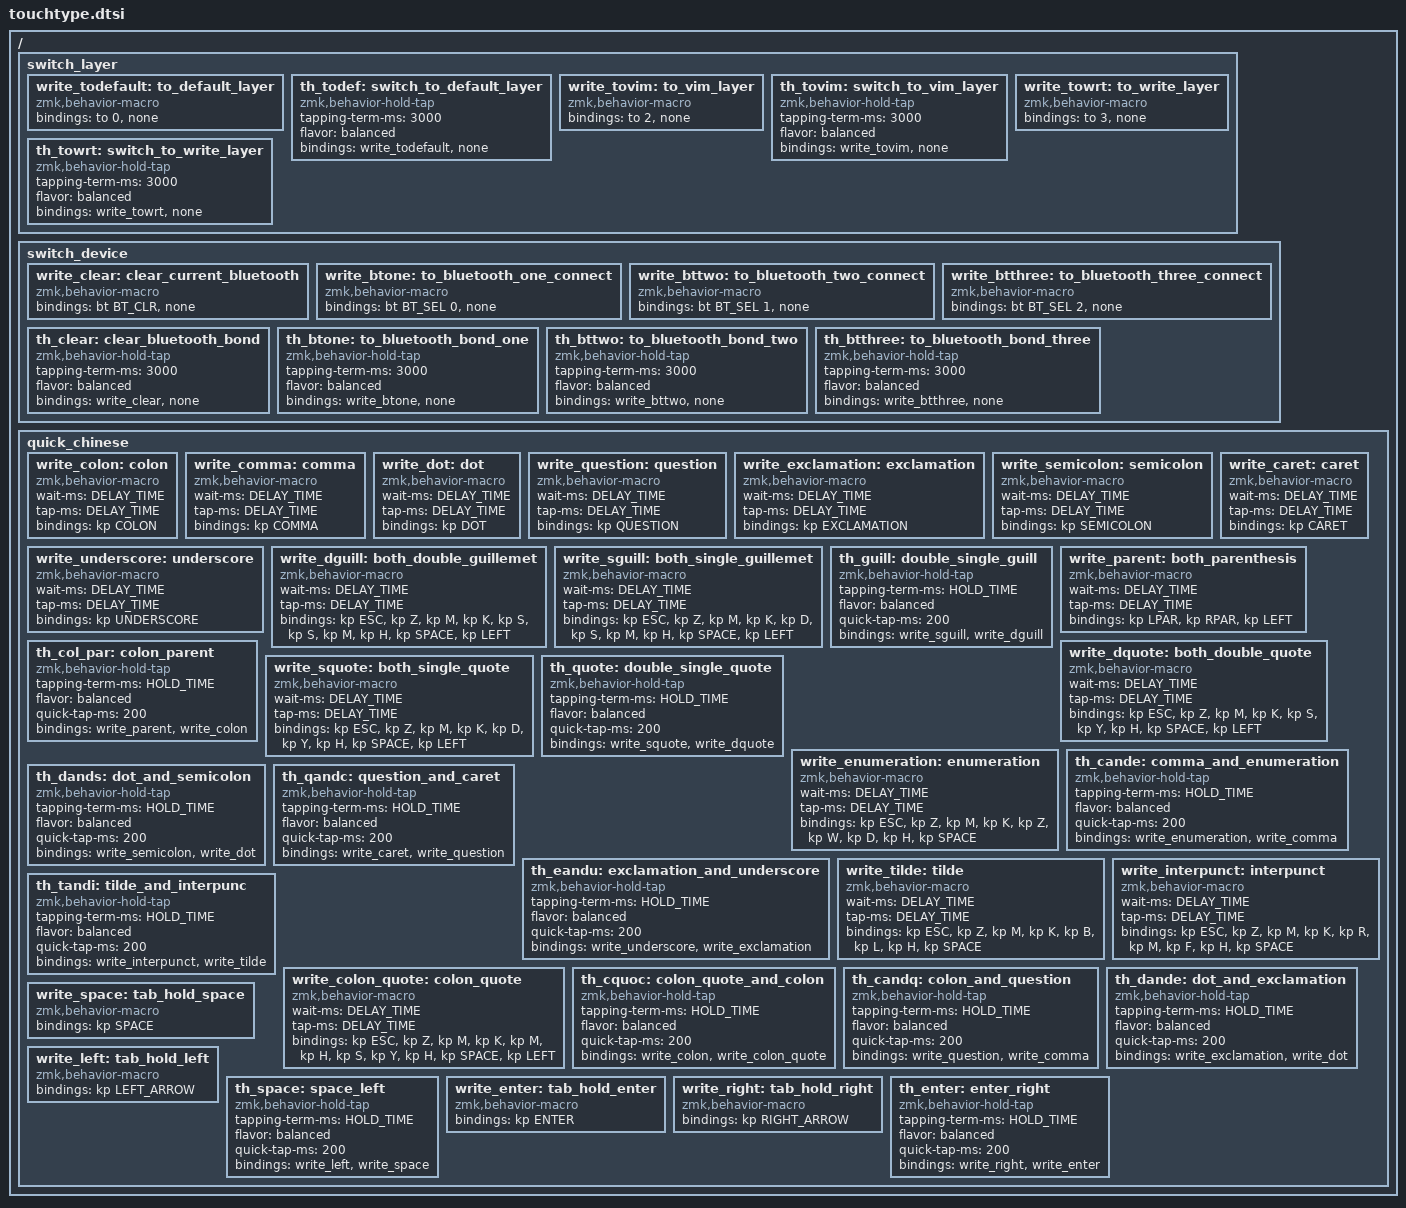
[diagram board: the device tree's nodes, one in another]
// 自定义符号快捷输入

#define DELAY_TIME <5> // 定义宏延迟时间为 10 毫秒
#define HOLD_TIME <500> // 定义短按、长按时间阀值


/ { 
    // 切换到不同编辑模式层
    switch_layer {
        // 如果有自定义行为，就需要把 &none 更换成真实的 behavior，例如 <&to 0 &kp A>，下面其实类似
        write_todefault: to_default_layer {
            compatible = "zmk,behavior-macro";
            #binding-cells = <0>;   
            bindings = <&to 0 &none>;
        }; 

         // 短按空按键 ，长按切换到默认 layer 0
        th_todef: switch_to_default_layer {
            compatible = "zmk,behavior-hold-tap";
            #binding-cells = <2>;
            tapping-term-ms = <3000>;      // 短按判定时间，可调
            flavor = "balanced";          // 推荐 balanced，更自然
            // 长按在前，短按在后；同时适用于 windows 和 linux 输入法
            bindings = <&write_todefault>,<&none>;
        }; 

        write_tovim: to_vim_layer {
            compatible = "zmk,behavior-macro";
            #binding-cells = <0>;   
            bindings = <&to 2 &none>;
        }; 

         // 短按空按键 ，长按切换到 vim 编辑层 layer 1
        th_tovim: switch_to_vim_layer {
            compatible = "zmk,behavior-hold-tap";
            #binding-cells = <2>;
            tapping-term-ms = <3000>;      // 短按判定时间，可调
            flavor = "balanced";          // 推荐 balanced，更自然
            // 长按在前，短按在后；同时适用于 windows 和 linux 输入法
            bindings = <&write_tovim>,<&none>;
        }; 

        write_towrt: to_write_layer {
            compatible = "zmk,behavior-macro";
            #binding-cells = <0>;   
            bindings = <&to 3 &none>;
        }; 

         // 短按空按键 ，长按切换到写作模式层 layer 2
        th_towrt: switch_to_write_layer {
            compatible = "zmk,behavior-hold-tap";
            #binding-cells = <2>;
            tapping-term-ms = <3000>;      // 短按判定时间，可调
            flavor = "balanced";          // 推荐 balanced，更自然
            // 长按在前，短按在后；同时适用于 windows 和 linux 输入法
            bindings = <&write_towrt>,<&none>;
        }; 

    };

    // 切换不同的连接主机
    switch_device {
        // 主机清除当前槽位的匹配信息之后，需要在 zmk 的相同槽位清除匹配信息，它不会影响其它槽位的匹配信息
        // 如果有自定义行为，就需要把 &none 更换成真实的 behavior，下面其实类似
        write_clear: clear_current_bluetooth {
            compatible = "zmk,behavior-macro";
            #binding-cells = <0>;   
            bindings = <&bt BT_CLR &none>;
        };

        // 切换到槽位 0 的蓝牙连接
        write_btone: to_bluetooth_one_connect {
            compatible = "zmk,behavior-macro";
            #binding-cells = <0>;   
            bindings = <&bt BT_SEL 0 &none>;
        };

        // 切换到槽位 1 的蓝牙连接
        write_bttwo: to_bluetooth_two_connect {
            compatible = "zmk,behavior-macro";
            #binding-cells = <0>;   
            bindings = <&bt BT_SEL 1 &none>;
        };

        //切换到槽位 2 的蓝牙连接 
        write_btthree: to_bluetooth_three_connect {
            compatible = "zmk,behavior-macro";
            #binding-cells = <0>;   
            bindings = <&bt BT_SEL 2 &none>;
        };   
         // 短按空按键 ，长按清除当前槽位的蓝牙连接匹配
        th_clear: clear_bluetooth_bond {
            compatible = "zmk,behavior-hold-tap";
            #binding-cells = <2>;
            tapping-term-ms = <3000>;      // 短按判定时间，可调
            flavor = "balanced";          // 推荐 balanced，更自然
            // 长按在前，短按在后；同时适用于 windows 和 linux 输入法
            bindings = <&write_clear>,<&none>;
        };   

         // 短按空按键 ，长按切换到蓝牙连接槽位 0
        th_btone: to_bluetooth_bond_one {
            compatible = "zmk,behavior-hold-tap";
            #binding-cells = <2>;
            tapping-term-ms = <3000>;      // 短按判定时间，可调
            flavor = "balanced";          // 推荐 balanced，更自然
            // 长按在前，短按在后；同时适用于 windows 和 linux 输入法
            bindings = <&write_btone>,<&none>;
        };  

         // 短按空按键 ，长按切换到蓝牙连接槽位 1
        th_bttwo: to_bluetooth_bond_two {
            compatible = "zmk,behavior-hold-tap";
            #binding-cells = <2>;
            tapping-term-ms = <3000>;      // 短按判定时间，可调
            flavor = "balanced";          // 推荐 balanced，更自然
            // 长按在前，短按在后；同时适用于 windows 和 linux 输入法
            bindings = <&write_bttwo>,<&none>;
        };       

         // 短按空按键 ，长按切换到蓝牙连接槽位 0
        th_btthree: to_bluetooth_bond_three {
            compatible = "zmk,behavior-hold-tap";
            #binding-cells = <2>;
            tapping-term-ms = <3000>;      // 短按判定时间，可调
            flavor = "balanced";          // 推荐 balanced，更自然
            // 长按在前，短按在后；同时适用于 windows 和 linux 输入法
            bindings = <&write_btthree>,<&none>;
        };    
    };

    // 快速输入中文符号
    quick_chinese {
        // ------------------- 一些共用按键 ------------------
        // 输入 ： 冒号
        write_colon: colon {
            compatible = "zmk,behavior-macro";
            #binding-cells = <0>;   
            wait-ms = DELAY_TIME;
            tap-ms = DELAY_TIME;
            // linux不需要额外设置，windows不确定需不需要额外设置
            bindings = <&kp COLON>;
        };

        // 输入 ， 逗号
        write_comma: comma {
            compatible = "zmk,behavior-macro";
            #binding-cells = <0>;   
            wait-ms = DELAY_TIME;
            tap-ms = DELAY_TIME;
            // linux不需要额外设置，windows不确定需不需要额外设置
            bindings = <&kp COMMA>;
        };

        // 输入 。 句号
        write_dot: dot {
            compatible = "zmk,behavior-macro";
            #binding-cells = <0>;   
            wait-ms = DELAY_TIME;
            tap-ms = DELAY_TIME;
            // linux不需要额外设置，windows不确定需不需要额外设置
            bindings = <&kp DOT>;
        };

        // 输入 ？ 问号
        write_question: question {
            compatible = "zmk,behavior-macro";
            #binding-cells = <0>;   
            wait-ms = DELAY_TIME;
            tap-ms = DELAY_TIME;
            // linux不需要额外设置，windows不确定需不需要额外设置
            bindings = <&kp QUESTION>;
        };

        // 输入 ！ 感叹号
        write_exclamation: exclamation {
            compatible = "zmk,behavior-macro";
            #binding-cells = <0>;   
            wait-ms = DELAY_TIME;
            tap-ms = DELAY_TIME;
            // linux不需要额外设置，windows不确定需不需要额外设置
            bindings = <&kp EXCLAMATION>;
        };   

        // 输入 ； 分号
        write_semicolon: semicolon {
            compatible = "zmk,behavior-macro";
            #binding-cells = <0>;   
            wait-ms = DELAY_TIME;
            tap-ms = DELAY_TIME;
            // linux不需要额外设置，windows不确定需不需要额外设置
            bindings = <&kp SEMICOLON>;
        };

        // 输入 …… 分号
        write_caret: caret {
            compatible = "zmk,behavior-macro";
            #binding-cells = <0>;   
            wait-ms = DELAY_TIME;
            tap-ms = DELAY_TIME;
            // linux不需要额外设置，windows不确定需不需要额外设置
            bindings = <&kp CARET>;
        };

        // 输入 —— 分号
        write_underscore: underscore {
            compatible = "zmk,behavior-macro";
            #binding-cells = <0>;   
            wait-ms = DELAY_TIME;
            tap-ms = DELAY_TIME;
            // linux不需要额外设置，windows不确定需不需要额外设置
            bindings = <&kp UNDERSCORE>;
        };

        // ----------------- R1C4 默认键位值 -----------------
        // 输入左、右双书名号、左方向键
        write_dguill: both_double_guillemet {
            compatible = "zmk,behavior-macro";
            #binding-cells = <0>;   
            wait-ms = DELAY_TIME;
            tap-ms = DELAY_TIME;
            // 需要在输入法当中添加 zmkssmh → 《》 这样的定义才能使用，同时适用于 windows 和 linux 输入法
            bindings = <&kp ESC &kp Z &kp M &kp K &kp S &kp S &kp M &kp H &kp SPACE &kp LEFT>;
        };

        // 输入左、右单书名呈、左方向键
        write_sguill: both_single_guillemet {
            compatible = "zmk,behavior-macro";
            #binding-cells = <0>;   
            wait-ms = DELAY_TIME;
            tap-ms = DELAY_TIME;
            // 需要在输入法当中添加 zmkysyh → 《》 这样的定义才能使用，同时适用于 windows 和 linux 输入法
            bindings = <&kp ESC &kp Z &kp M &kp K &kp D &kp S &kp M &kp H &kp SPACE &kp LEFT>;
        };

        // 短按输出 《》，长按输出 〈〉
        th_guill: double_single_guill {
            compatible = "zmk,behavior-hold-tap";
            #binding-cells = <2>;
            tapping-term-ms = HOLD_TIME;      // 短按判定时间，可调
            flavor = "balanced";          // 推荐 balanced，更自然
            quick-tap-ms = <200>;         // 快速连点也按 tap 处理（可选）
            // 长按在前，短按在后；同时适用于 windows 和 linux 输入法
            bindings =<&write_sguill>, <&write_dguill> ;
        };


        // ----------------- R1C5 默认键位值 -----------------
        // 输入左、右括号、左方向键
        write_parent: both_parenthesis {
            compatible = "zmk,behavior-macro";
            #binding-cells = <0>;   
            wait-ms = DELAY_TIME;
            tap-ms = DELAY_TIME;
            // linux不需要额外设置，windows不确定需不需要额外设置
            bindings = <&kp LPAR &kp RPAR &kp LEFT>;
        };

        // 短按输出 ：，长按输出 （）
        th_col_par: colon_parent {
            compatible = "zmk,behavior-hold-tap";
            #binding-cells = <2>;
            tapping-term-ms = HOLD_TIME;      // 短按判定时间，可调
            flavor = "balanced";          // 推荐 balanced，更自然
            quick-tap-ms = <200>;         // 快速连点也按 tap 处理（可选）
            // 长按在前，短按在后；同时适用于 windows 和 linux 输入法
            bindings =<&write_parent>, <&write_colon>;
        };   

        
        // ----------------- R1C6 默认键位值 -----------------   
        // 输入左双引号、右双引号、左方向键
        write_dquote: both_double_quote {
            compatible = "zmk,behavior-macro";
            #binding-cells = <0>;   
            wait-ms = DELAY_TIME;
            tap-ms = DELAY_TIME;
            // 需要在输入法当中添加 zmksyh → “” 这样的定义才能使用，同时适用于 windows 和 linux 输入法
            bindings = <&kp ESC &kp Z &kp M &kp K &kp S &kp Y &kp H &kp SPACE &kp LEFT>;
        };

        // 输入左单引号、右单引号、左方向键
        write_squote: both_single_quote {
            compatible = "zmk,behavior-macro";
            #binding-cells = <0>;   
            wait-ms = DELAY_TIME;
            tap-ms = DELAY_TIME;
            // 需要在输入法当中添加 zmkdyh → ‘’ 这样的定义才能使用，同时适用于 windows 和 linux 输入法
            bindings = <&kp ESC &kp Z &kp M &kp K &kp D &kp Y &kp H &kp SPACE &kp LEFT>;
        };

        // 短按输出 “”，长按输出 ‘’
        th_quote: double_single_quote {
            compatible = "zmk,behavior-hold-tap";
            #binding-cells = <2>;
            tapping-term-ms = HOLD_TIME;      // 短按判定时间，可调
            flavor = "balanced";          // 推荐 balanced，更自然
            quick-tap-ms = <200>;         // 快速连点也按 tap 处理（可选）
            // 长按在前，短按在后；同时适用于 windows 和 linux 输入法
            bindings =<&write_squote>, <&write_dquote> ;
        };


        // ----------------- R1C7 默认键位值 -----------------
        // 输入 、 顿号
        write_enumeration: enumeration {
            compatible = "zmk,behavior-macro";
            #binding-cells = <0>;   
            wait-ms = DELAY_TIME;
            tap-ms = DELAY_TIME;
            // 需要在输入法当中添加 zmkzwdh → 、 这样的定义才能使用，同时适用于 windows 和 linux 输入法
            bindings = <&kp ESC &kp Z &kp M &kp K &kp Z &kp W &kp D &kp H &kp SPACE>;
        };

        // 短按输出 ，，长按输出 、
        th_cande: comma_and_enumeration {
            compatible = "zmk,behavior-hold-tap";
            #binding-cells = <2>;
            tapping-term-ms = HOLD_TIME;      // 短按判定时间，可调
            flavor = "balanced";          // 推荐 balanced，更自然
            quick-tap-ms = <200>;         // 快速连点也按 tap 处理（可选）
            // 长按在前，短按在后；同时适用于 windows 和 linux 输入法
            bindings =<&write_enumeration>, <&write_comma>;
        };  


        // ----------------- R1C8 默认键位值 -----------------
        // 短按输出 。，长按输出 ；
        th_dands: dot_and_semicolon {
            compatible = "zmk,behavior-hold-tap";
            #binding-cells = <2>;
            tapping-term-ms = HOLD_TIME;      // 短按判定时间，可调
            flavor = "balanced";          // 推荐 balanced，更自然
            quick-tap-ms = <200>;         // 快速连点也按 tap 处理（可选）
            // 长按在前，短按在后；同时适用于 windows 和 linux 输入法
            bindings =<&write_semicolon>, <&write_dot>;
        };                   


        // ----------------- R1C9 默认键位值 -----------------
        // 短按输出 ？，长按输出 ……
        th_qandc: question_and_caret {
            compatible = "zmk,behavior-hold-tap";
            #binding-cells = <2>;
            tapping-term-ms = HOLD_TIME;      // 短按判定时间，可调
            flavor = "balanced";          // 推荐 balanced，更自然
            quick-tap-ms = <200>;         // 快速连点也按 tap 处理（可选）
            // 长按在前，短按在后；同时适用于 windows 和 linux 输入法
            bindings =<&write_caret>, <&write_question>;
        };


        // ----------------- R6C1 默认键位值 -----------------   
        // 短按输出 ！，长按输出 ——
        th_eandu: exclamation_and_underscore {
            compatible = "zmk,behavior-hold-tap";
            #binding-cells = <2>;
            tapping-term-ms = HOLD_TIME;      // 短按判定时间，可调
            flavor = "balanced";          // 推荐 balanced，更自然
            quick-tap-ms = <200>;         // 快速连点也按 tap 处理（可选）
            // 长按在前，短按在后；同时适用于 windows 和 linux 输入法
            bindings =<&write_underscore>, <&write_exclamation>;
        };


        // ----------------- R6C1 默认键位值 -----------------   
        // 输入 ~ 波浪号
        write_tilde: tilde {
            compatible = "zmk,behavior-macro";
            #binding-cells = <0>;   
            wait-ms = DELAY_TIME;
            tap-ms = DELAY_TIME;
            // 需要在输入法当中添加 zmkblh → ~ 这样的定义才能使用，同时适用于 windows 和 linux 输入法
            bindings = <&kp ESC &kp Z &kp M &kp K &kp B &kp L &kp H &kp SPACE>;
        };

        // 输入 • 人名分隔号
        write_interpunct: interpunct {
            compatible = "zmk,behavior-macro";
            #binding-cells = <0>;   
            wait-ms = DELAY_TIME;
            tap-ms = DELAY_TIME;
            // 需要在输入法当中添加 zmkrmfgh → • 这样的定义才能使用，同时适用于 windows 和 linux 输入法
            bindings = <&kp ESC &kp Z &kp M &kp K &kp R &kp M &kp F &kp H &kp SPACE>;
        };

        // 短按输出 ~，长按输出 •
        th_tandi: tilde_and_interpunc {
            compatible = "zmk,behavior-hold-tap";
            #binding-cells = <2>;
            tapping-term-ms = HOLD_TIME;      // 短按判定时间，可调
            flavor = "balanced";          // 推荐 balanced，更自然
            quick-tap-ms = <200>;         // 快速连点也按 tap 处理（可选）
            // 长按在前，短按在后；同时适用于 windows 和 linux 输入法
            bindings =<&write_interpunct>, <&write_tilde>;
        };  


        // ----------------- R8C2 默认键位值 -----------------   
        // 输入 ：“” 冒号双引号
        write_colon_quote: colon_quote {
            compatible = "zmk,behavior-macro";
            #binding-cells = <0>;   
            wait-ms = DELAY_TIME;
            tap-ms = DELAY_TIME;
            // 需要在输入法当中添加 zmkmhsyh → ：“” 这样的定义才能使用，同时适用于 windows 和 linux 输入法
            bindings = <&kp ESC &kp Z &kp M &kp K &kp M &kp H &kp S &kp Y &kp H &kp SPACE &kp LEFT>;
        };

        // 短按输出 :""，长按输出 :
        th_cquoc: colon_quote_and_colon {
            compatible = "zmk,behavior-hold-tap";
            #binding-cells = <2>;
            tapping-term-ms = HOLD_TIME;      // 短按判定时间，可调
            flavor = "balanced";          // 推荐 balanced，更自然
            quick-tap-ms = <200>;         // 快速连点也按 tap 处理（可选）
            // 长按在前，短按在后；同时适用于 windows 和 linux 输入法
            bindings =<&write_colon>, <&write_colon_quote>;
        };                


        // ----------------- R4C9 默认键位值 -----------------   
        // 短按输出 ,，长按输出 ?
        th_candq: colon_and_question {
            compatible = "zmk,behavior-hold-tap";
            #binding-cells = <2>;
            tapping-term-ms = HOLD_TIME;      // 短按判定时间，可调
            flavor = "balanced";          // 推荐 balanced，更自然
            quick-tap-ms = <200>;         // 快速连点也按 tap 处理（可选）
            // 长按在前，短按在后；同时适用于 windows 和 linux 输入法
            bindings =<&write_question>, <&write_comma>;
        }; 


        // ----------------- R9C1 默认键位值 -----------------   
        // 短按输出 。，长按输出 ！
        th_dande: dot_and_exclamation {
            compatible = "zmk,behavior-hold-tap";
            #binding-cells = <2>;
            tapping-term-ms = HOLD_TIME;      // 短按判定时间，可调
            flavor = "balanced";          // 推荐 balanced，更自然
            quick-tap-ms = <200>;         // 快速连点也按 tap 处理（可选）
            // 长按在前，短按在后；同时适用于 windows 和 linux 输入法
            bindings =<&write_exclamation>, <&write_dot>;
        };


        // ----------------- R5C4 默认键位值 -----------------   
        // 输入 Space 空格键
        write_space: tab_hold_space {
            compatible = "zmk,behavior-macro";
            #binding-cells = <0>;   
            bindings = <&kp SPACE>;
        };

        // 输入 ← 左方向键
        write_left: tab_hold_left {
            compatible = "zmk,behavior-macro";
            #binding-cells = <0>;   
            bindings = <&kp LEFT_ARROW>;
        };

        // 短按输出 space ，长按输出 ←
        th_space: space_left {
            compatible = "zmk,behavior-hold-tap";
            #binding-cells = <2>;
            tapping-term-ms = HOLD_TIME;      // 短按判定时间，可调
            flavor = "balanced";          // 推荐 balanced，更自然
            quick-tap-ms = <200>;         // 快速连点也按 tap 处理（可选）
            // 长按在前，短按在后；同时适用于 windows 和 linux 输入法
            bindings = <&write_left>,<&write_space>;
        };  


        // ----------------- R5C5 默认键位值 -----------------   
        // 输出 Enter 确定键
        write_enter: tab_hold_enter {
            compatible = "zmk,behavior-macro";
            #binding-cells = <0>;   
            bindings = <&kp ENTER>;
        };

        // 输出 → 右方向键
        write_right: tab_hold_right {
            compatible = "zmk,behavior-macro";
            #binding-cells = <0>;   
            bindings = <&kp RIGHT_ARROW>;
        };

        // 短按输出 enter ，长按输出 →
        th_enter: enter_right {
            compatible = "zmk,behavior-hold-tap";
            #binding-cells = <2>;
            tapping-term-ms = HOLD_TIME;      // 短按判定时间，可调
            flavor = "balanced";          // 推荐 balanced，更自然
            quick-tap-ms = <200>;         // 快速连点也按 tap 处理（可选）
            // 长按在前，短按在后；同时适用于 windows 和 linux 输入法
            bindings = <&write_right>,<&write_enter>;
        };









    };
};
